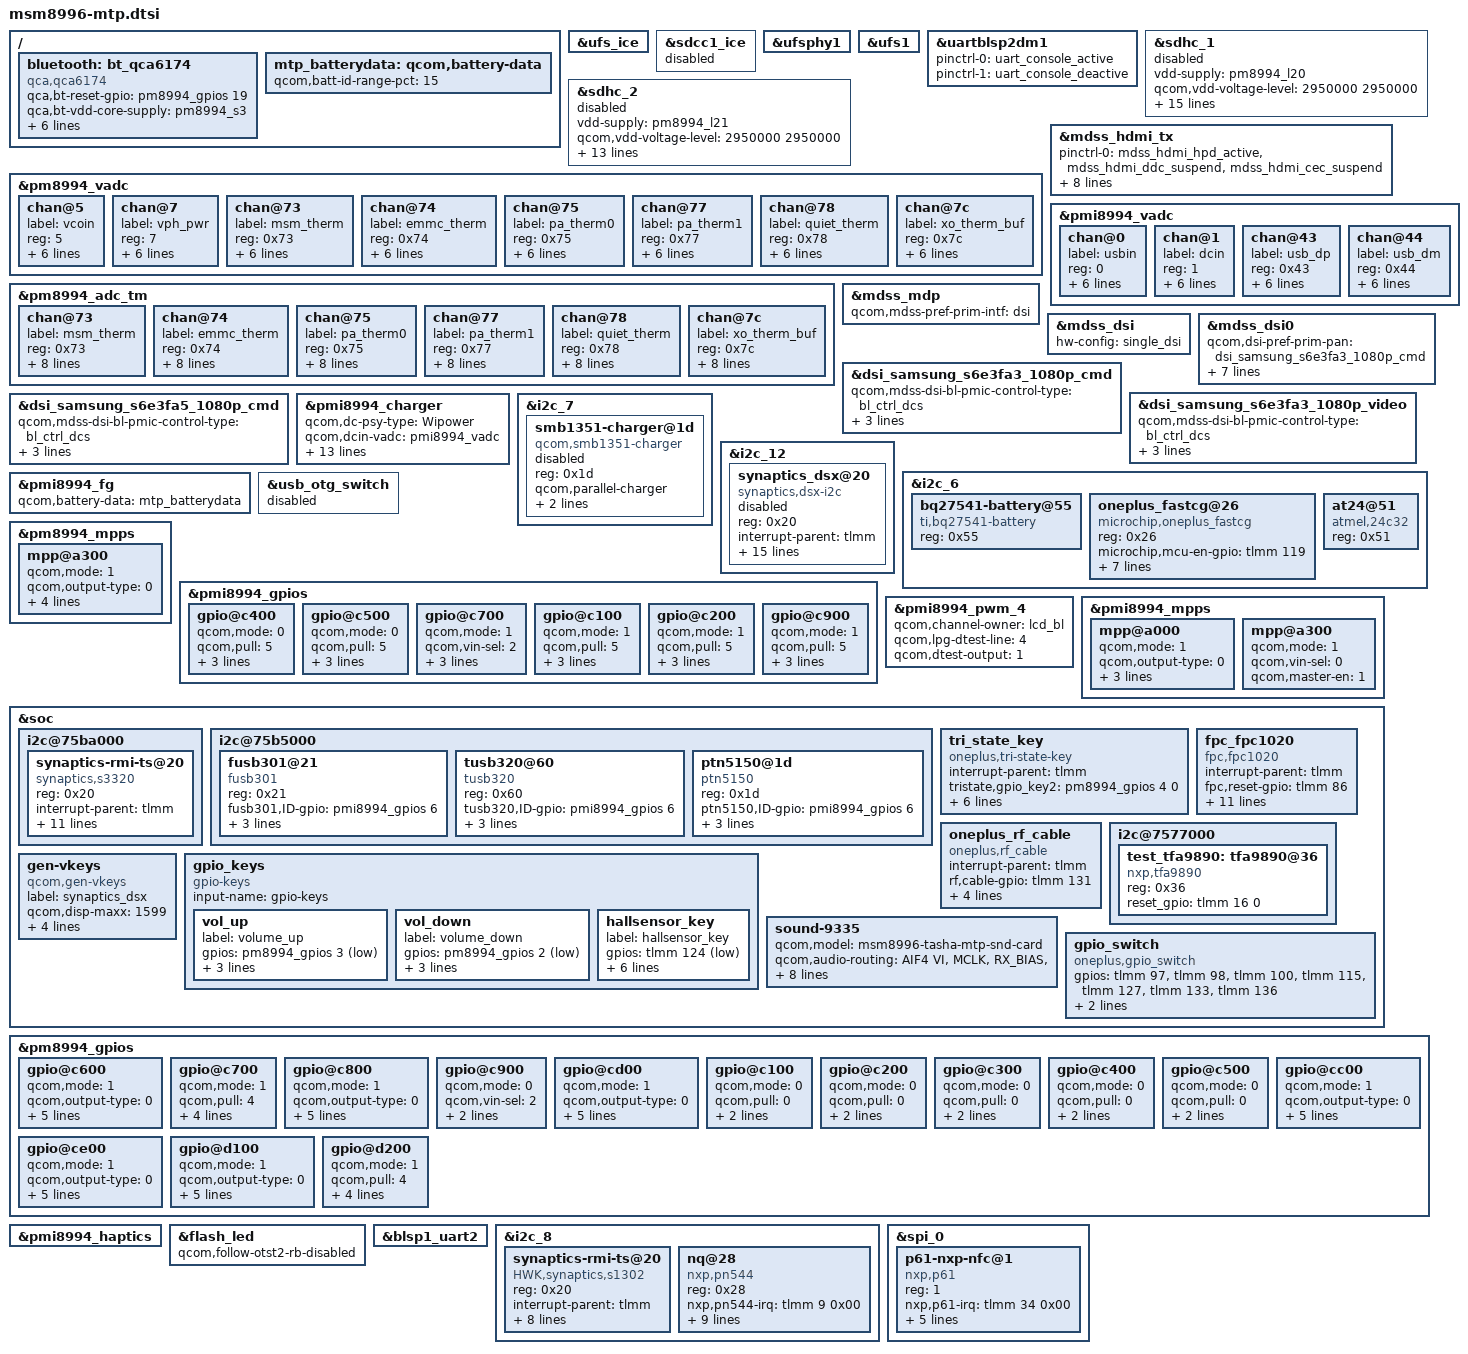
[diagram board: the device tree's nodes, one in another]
/* Copyright (c) 2015, The Linux Foundation. All rights reserved.
 *
 * This program is free software; you can redistribute it and/or modify
 * it under the terms of the GNU General Public License version 2 and
 * only version 2 as published by the Free Software Foundation.
 *
 * This program is distributed in the hope that it will be useful,
 * but WITHOUT ANY WARRANTY; without even the implied warranty of
 * MERCHANTABILITY or FITNESS FOR A PARTICULAR PURPOSE.  See the
 * GNU General Public License for more details.
 */

#include "msm8996-pinctrl.dtsi"
#include "msm8996-camera-sensor-mtp.dtsi"
#include "dsi-panel-samsung_s6e3fa3_1080p_cmd.dtsi"  //guozhiming modify for lcd 2015-10-15


/ {
	bluetooth: bt_qca6174 {
		compatible = "qca,qca6174";
		qca,bt-reset-gpio = <&pm8994_gpios 19 0>; /* BT_EN */
		qca,bt-vdd-core-supply = <&pm8994_s3>;
		qca,bt-vdd-pa-supply = <&rome_vreg>;
		qca,bt-vdd-io-supply = <&pm8994_s4>;
		qca,bt-vdd-xtal-supply = <&pm8994_l30>;
		qca,bt-chip-pwd-voltage-level = <1300000 1300000>;
		qca,bt-vdd-io-voltage-level = <1800000 1800000>;
		qca,bt-vdd-xtal-voltage-level = <1800000 1800000>;
	};
};

&ufs_ice {
        status = "ok";
};

&sdcc1_ice {
        /*zuoyonghua@connectivity 2015 12 07 hw11(T0) we used ufs , don't used emmc ,so disable it*/
        status = "disabled";
};

&ufsphy1 {
	status = "ok";
};

&ufs1 {
	status = "ok";
};

&uartblsp2dm1 {
	status = "ok";
	pinctrl-names = "uart_active", "uart_deactive";
	pinctrl-0 = <&uart_console_active>;
	pinctrl-1 = <&uart_console_deactive>;
};

&sdhc_1 {
	vdd-supply = <&pm8994_l20>;
	qcom,vdd-voltage-level = <2950000 2950000>;
	qcom,vdd-current-level = <200 570000>;

	vdd-io-supply = <&pm8994_s4>;
	qcom,vdd-io-always-on;
	qcom,vdd-io-voltage-level = <1800000 1800000>;
	qcom,vdd-io-current-level = <110 325000>;

	pinctrl-names = "active", "sleep";
	pinctrl-0 = <&sdc1_clk_on &sdc1_cmd_on &sdc1_data_on &sdc1_rclk_on>;
	pinctrl-1 = <&sdc1_clk_off &sdc1_cmd_off &sdc1_data_off &sdc1_rclk_off>;

	qcom,clk-rates = <400000 20000000 25000000 50000000 96000000 192000000 384000000>;
	qcom,ice-clk-rates = <300000000 150000000>;
	qcom,nonremovable;
	qcom,bus-speed-mode = "HS400_1p8v", "HS200_1p8v", "DDR_1p8v";

	/*zuoyonghua@connectivity 2015 12 07 hw11(T0) we used ufs , don't used emmc ,so disable it*/
	status = "disabled";
};

&sdhc_2 {
	vdd-supply = <&pm8994_l21>;
	qcom,vdd-voltage-level = <2950000 2950000>;
	qcom,vdd-current-level = <200 800000>;

	vdd-io-supply = <&pm8994_l13>;
	qcom,vdd-io-voltage-level = <1800000 2950000>;
	qcom,vdd-io-current-level = <200 22000>;

	pinctrl-names = "active", "sleep";
	pinctrl-0 = <&sdc2_clk_on  &sdc2_cmd_on &sdc2_data_on &sdc2_cd_on>;
	pinctrl-1 = <&sdc2_clk_off &sdc2_cmd_off &sdc2_data_off &sdc2_cd_off>;

	qcom,clk-rates = <400000 20000000 25000000 50000000 100000000 200000000>;
	qcom,bus-speed-mode = "SDR12", "SDR25", "SDR50", "DDR50", "SDR104";

	cd-gpios = <&tlmm 95 0x1>;
	/*lyb@bsp 11/17/15: 15801 L13/L21 don't used for MicroSD*/
	status = "disable";
};

&pm8994_vadc {
	chan@5 {
		label = "vcoin";
		reg = <5>;
		qcom,decimation = <0>;
		qcom,pre-div-channel-scaling = <1>;
		qcom,calibration-type = "absolute";
		qcom,scale-function = <0>;
		qcom,hw-settle-time = <0>;
		qcom,fast-avg-setup = <0>;
	};

	chan@7 {
		label = "vph_pwr";
		reg = <7>;
		qcom,decimation = <0>;
		qcom,pre-div-channel-scaling = <1>;
		qcom,calibration-type = "absolute";
		qcom,scale-function = <0>;
		qcom,hw-settle-time = <0>;
		qcom,fast-avg-setup = <0>;
	};

	chan@73 {
		label = "msm_therm";
		reg = <0x73>;
		qcom,decimation = <0>;
		qcom,pre-div-channel-scaling = <0>;
		qcom,calibration-type = "ratiometric";
		qcom,scale-function = <2>;
		qcom,hw-settle-time = <2>;
		qcom,fast-avg-setup = <0>;
	};

	chan@74 {
		label = "emmc_therm";
		reg = <0x74>;
		qcom,decimation = <0>;
		qcom,pre-div-channel-scaling = <0>;
		qcom,calibration-type = "ratiometric";
		qcom,scale-function = <2>;
		qcom,hw-settle-time = <2>;
		qcom,fast-avg-setup = <0>;
	};

	chan@75 {
		label = "pa_therm0";
		reg = <0x75>;
		qcom,decimation = <0>;
		qcom,pre-div-channel-scaling = <0>;
		qcom,calibration-type = "ratiometric";
		qcom,scale-function = <2>;
		qcom,hw-settle-time = <2>;
		qcom,fast-avg-setup = <0>;
	};

	chan@77 {
		label = "pa_therm1";
		reg = <0x77>;
		qcom,decimation = <0>;
		qcom,pre-div-channel-scaling = <0>;
		qcom,calibration-type = "ratiometric";
		qcom,scale-function = <2>;
		qcom,hw-settle-time = <2>;
		qcom,fast-avg-setup = <0>;
	};

	chan@78 {
		label = "quiet_therm";
		reg = <0x78>;
		qcom,decimation = <0>;
		qcom,pre-div-channel-scaling = <0>;
		qcom,calibration-type = "ratiometric";
		qcom,scale-function = <2>;
		qcom,hw-settle-time = <2>;
		qcom,fast-avg-setup = <0>;
	};

	chan@7c {
		label = "xo_therm_buf";
		reg = <0x7c>;
		qcom,decimation = <0>;
		qcom,pre-div-channel-scaling = <0>;
		qcom,calibration-type = "ratiometric";
		qcom,scale-function = <4>;
		qcom,hw-settle-time = <2>;
		qcom,fast-avg-setup = <0>;
	};

	chan@7c {
		label = "xo_therm_buf";
		reg = <0x7c>;
		qcom,decimation = <0>;
		qcom,pre-div-channel-scaling = <0>;
		qcom,calibration-type = "ratiometric";
		qcom,scale-function = <4>;
		qcom,hw-settle-time = <2>;
		qcom,fast-avg-setup = <0>;
	};
};

&pm8994_adc_tm {
	chan@73 {
		label = "msm_therm";
		reg = <0x73>;
		qcom,decimation = <0>;
		qcom,pre-div-channel-scaling = <0>;
		qcom,calibration-type = "ratiometric";
		qcom,scale-function = <2>;
		qcom,hw-settle-time = <2>;
		qcom,fast-avg-setup = <0>;
		qcom,btm-channel-number = <0x48>;
		qcom,thermal-node;
	};

	chan@74 {
		label = "emmc_therm";
		reg = <0x74>;
		qcom,decimation = <0>;
		qcom,pre-div-channel-scaling = <0>;
		qcom,calibration-type = "ratiometric";
		qcom,scale-function = <2>;
		qcom,hw-settle-time = <2>;
		qcom,fast-avg-setup = <0>;
		qcom,btm-channel-number = <0x68>;
		qcom,thermal-node;
	};

	chan@75 {
		label = "pa_therm0";
		reg = <0x75>;
		qcom,decimation = <0>;
		qcom,pre-div-channel-scaling = <0>;
		qcom,calibration-type = "ratiometric";
		qcom,scale-function = <2>;
		qcom,hw-settle-time = <2>;
		qcom,fast-avg-setup = <0>;
		qcom,btm-channel-number = <0x70>;
		qcom,thermal-node;
	};

	chan@77 {
		label = "pa_therm1";
		reg = <0x77>;
		qcom,decimation = <0>;
		qcom,pre-div-channel-scaling = <0>;
		qcom,calibration-type = "ratiometric";
		qcom,scale-function = <2>;
		qcom,hw-settle-time = <2>;
		qcom,fast-avg-setup = <0>;
		qcom,btm-channel-number = <0x78>;
		qcom,thermal-node;
	};

	chan@78 {
		label = "quiet_therm";
		reg = <0x78>;
		qcom,decimation = <0>;
		qcom,pre-div-channel-scaling = <0>;
		qcom,calibration-type = "ratiometric";
		qcom,scale-function = <2>;
		qcom,hw-settle-time = <2>;
		qcom,fast-avg-setup = <0>;
		qcom,btm-channel-number = <0x80>;
		qcom,thermal-node;
	};

	chan@7c {
		label = "xo_therm_buf";
		reg = <0x7c>;
		qcom,decimation = <0>;
		qcom,pre-div-channel-scaling = <0>;
		qcom,calibration-type = "ratiometric";
		qcom,scale-function = <4>;
		qcom,hw-settle-time = <2>;
		qcom,fast-avg-setup = <0>;
		qcom,btm-channel-number = <0x88>;
		qcom,thermal-node;
	};
};

&mdss_hdmi_tx {
	pinctrl-names = "hdmi_hpd_active", "hdmi_ddc_active", "hdmi_cec_active",
				"hdmi_active", "hdmi_sleep";
	pinctrl-0 = <&mdss_hdmi_hpd_active &mdss_hdmi_ddc_suspend
						&mdss_hdmi_cec_suspend>;
	pinctrl-1 = <&mdss_hdmi_hpd_active &mdss_hdmi_ddc_active
						&mdss_hdmi_cec_suspend>;
	pinctrl-2 = <&mdss_hdmi_hpd_active &mdss_hdmi_cec_active
						&mdss_hdmi_ddc_suspend>;
	pinctrl-3 = <&mdss_hdmi_hpd_active &mdss_hdmi_ddc_active
						&mdss_hdmi_cec_active>;
	pinctrl-4 = <&mdss_hdmi_hpd_suspend &mdss_hdmi_ddc_suspend
						&mdss_hdmi_cec_suspend>;
};

&pmi8994_vadc {
	chan@0 {
		label = "usbin";
		reg = <0>;
		qcom,decimation = <0>;
		qcom,pre-div-channel-scaling = <4>;
		qcom,calibration-type = "absolute";
		qcom,scale-function = <0>;
		qcom,hw-settle-time = <0>;
		qcom,fast-avg-setup = <0>;
	};

	chan@1 {
		label = "dcin";
		reg = <1>;
		qcom,decimation = <0>;
		qcom,pre-div-channel-scaling = <4>;
		qcom,calibration-type = "absolute";
		qcom,scale-function = <0>;
		qcom,hw-settle-time = <0>;
		qcom,fast-avg-setup = <0>;
	};

	chan@43 {
		label = "usb_dp";
		reg = <0x43>;
		qcom,decimation = <0>;
		qcom,pre-div-channel-scaling = <1>;
		qcom,calibration-type = "absolute";
		qcom,scale-function = <0>;
		qcom,hw-settle-time = <0>;
		qcom,fast-avg-setup = <0>;
	};

	chan@44 {
		label = "usb_dm";
		reg = <0x44>;
		qcom,decimation = <0>;
		qcom,pre-div-channel-scaling = <1>;
		qcom,calibration-type = "absolute";
		qcom,scale-function = <0>;
		qcom,hw-settle-time = <0>;
		qcom,fast-avg-setup = <0>;
	};
};

#include "msm8996-mdss-panels.dtsi"


/*  //guozhiming modify for lcd 2015-10-15
&mdss_mdp {
	qcom,mdss-pref-prim-intf = "dsi";
};

&mdss_dsi {
	hw-config = "split_dsi";
};

&mdss_dsi0 {
	qcom,dsi-pref-prim-pan = <&dsi_dual_sharp_video>;
	pinctrl-names = "mdss_default", "mdss_sleep";
	pinctrl-0 = <&mdss_dsi_active &mdss_te_active>;
	pinctrl-1 = <&mdss_dsi_suspend &mdss_te_suspend>;
	qcom,platform-te-gpio = <&tlmm 10 0>;
	qcom,platform-reset-gpio = <&tlmm 8 0>;
	qcom,platform-bklight-en-gpio = <&pm8994_gpios 14 0>;
};

*/
//guozhiming modify for lcd 2015-10-15
&mdss_mdp {
	qcom,mdss-pref-prim-intf = "dsi";
};
&mdss_dsi {
	hw-config = "single_dsi";
};
&mdss_dsi0 {
	qcom,dsi-pref-prim-pan = <&dsi_samsung_s6e3fa3_1080p_cmd>;
	pinctrl-names = "mdss_default", "mdss_sleep";
	pinctrl-0 = <&mdss_dsi_active &mdss_te_active &mdss_exits_active &mdss_err_active>;
	pinctrl-1 = <&mdss_dsi_suspend &mdss_te_suspend &mdss_exits_suspend &mdss_err_suspend>;
	qcom,platform-te-gpio = <&tlmm 11 0>;
	qcom,platform-reset-gpio = <&tlmm 8 0>;
	//qcom,platform-esd-te-gpio = <&tlmm 11 0>;
	qcom,lcd-vddi-en-gpio = <&tlmm 26 0>;
};

&dsi_samsung_s6e3fa3_1080p_cmd {
	qcom,mdss-dsi-bl-pmic-control-type = "bl_ctrl_dcs";
	qcom,cont-splash-enabled;
	qcom,panel-supply-entries = <&dsi_panel_pwr_supply_no_labibb>;
};

&dsi_samsung_s6e3fa3_1080p_video {
       qcom,mdss-dsi-bl-pmic-control-type = "bl_ctrl_dcs";
       qcom,cont-splash-enabled;
       qcom,panel-supply-entries = <&dsi_panel_pwr_supply_no_labibb>;
};

&dsi_samsung_s6e3fa5_1080p_cmd {
	qcom,mdss-dsi-bl-pmic-control-type = "bl_ctrl_dcs";
	qcom,cont-splash-enabled;
	qcom,panel-supply-entries = <&dsi_panel_pwr_supply_no_labibb>;
};


/{
	mtp_batterydata: qcom,battery-data {
		qcom,batt-id-range-pct = <15>;
		#include "batterydata-itech-3000mah.dtsi"
	};
};

&pmi8994_charger {
	qcom,dc-psy-type = "Wipower";
	qcom,dcin-vadc = <&pmi8994_vadc>;
	qcom,wipower-default-ilim-map = <4000000 20000000 550 700 300>;
	qcom,wipower-pt-ilim-map = <4000000 7140000 550 700 300>,
					<7140000 8140000 550 700 300>,
					<8140000 9140000 500 700 300>,
					<9140000 9950000 500 700 300>;
	qcom,wipower-div2-ilim-map = <4000000 4820000 550 700 300>,
					<4820000 5820000 550 700 300>,
					<5820000 6820000 550 650 650>,
					<6820000 7820000 550 700 600>,
					<7820000 8500000 550 700 550>;
};

&i2c_7 {
	smb1351-charger@1d {
		compatible = "qcom,smb1351-charger";
		status = "disabled";
		reg = <0x1d>;
		qcom,parallel-charger;
		qcom,float-voltage-mv = <4400>;
		qcom,recharge-mv = <100>;
	};
};

&i2c_12 {
		synaptics_dsx@20 {
			compatible = "synaptics,dsx-i2c";
			reg = <0x20>;
			status = "disabled"; //T0 use new TP and LCD
			interrupt-parent = <&tlmm>;
			interrupts = <125 0x2008>;
			vdd_ana-supply = <&pm8994_l22>;
			vcc_i2c-supply = <&pm8994_s4>;
			synaptics,pwr-reg-name = "vdd_ana";
			synaptics,bus-reg-name = "vcc_i2c";
			synaptics,irq-gpio = <&tlmm 125 0x2008>;
			synaptics,irq-on-state = <0>;
			synaptics,irq-flags = <0x2008>; /* IRQF_ONESHOT | IRQF_TRIGGER_LOW */
			synaptics,power-gpio = <&tlmm 49 0x00>;
			synaptics,power-on-state = <1>;
			synaptics,power-delay-ms = <200>;
			synaptics,reset-delay-ms = <200>;
			synaptics,max-y-for-2d = <1919>; /* remove if no virtual buttons */
			//synaptics,vir-button-codes = <102 100 900 100 60 158 300 900 100 60>;
                        pinctrl-names = "pmx_ts_active", "pmx_ts_suspend";
                        pinctrl-0 = <&ts_active>;
                        pinctrl-1 = <&ts_suspend>;

		};
};

&i2c_6 {
	bq27541-battery@55 {
		status = "ok";
		compatible = "ti,bq27541-battery";
		reg = <0x55>;
	};
	oneplus_fastcg@26{
		status = "ok";
		compatible = "microchip,oneplus_fastcg";
		reg = <0x26>;
		microchip,mcu-en-gpio = <&tlmm 119 0x00>;
		microchip,usb-sw-gpio = <&tlmm 135 0x00>;
		microchip,ap-clk = <&tlmm 75 0x00>;
		microchip,ap-data = <&tlmm 74 0x00>;

		pinctrl-names = "mux_fastchg_active", "mux_fastchg_suspend";
		pinctrl-0 = <&fastchg_active &usb_sw_active &ap_clk_active &ap_data_active>;
		pinctrl-1 = <&usb_sw_suspend &fastchg_suspend &ap_clk_suspend &ap_data_suspend>;
	};
};

&pmi8994_fg {
	qcom,battery-data = <&mtp_batterydata>;
	//qcom,ext-sense-type;	/*Yangfangbiao removed to use internal sense*/
};

&usb_otg_switch {
	status = "disabled";//changhua change from okay to disabled
};

&pm8994_mpps {
	mpp@a300 { /* MPP 4 */
		/* HDMI_5v_vreg regulator enable */
		qcom,mode = <1>;		/* Digital output */
		qcom,output-type = <0>;		/* CMOS logic */
		qcom,vin-sel = <2>;		/* S4 1.8V */
		qcom,src-sel = <0>;		/* Constant */
		qcom,master-en = <1>;		/* Enable GPIO */
		qcom,invert = <0>;
		status = "okay";
	};
};

&pmi8994_gpios {
		gpio@c400 {//pmi8996 gpio 5 type-c IC INT pin
			qcom,mode = <0>;
			qcom,pull = <5>;
			qcom,vin-sel = <2>;
			qcom,src-sel = <0>;
			qcom,master-en = <1>;
			status = "okay";

		};

		gpio@c500 {//pmi8996 gpio 6 type-c IC OTG_USB_ID pin
			qcom,mode = <0>;
			qcom,pull = <5>;
			qcom,vin-sel = <2>;
			qcom,src-sel = <0>;
			qcom,master-en = <1>;
			status = "okay";
		};
};

&pmi8994_gpios {
	gpio@c700 {	/* GPIO 8, lcd_reg_en, 5V boost  */
		qcom,mode = <1>;
		qcom,vin-sel = <2>;
		qcom,src-sel = <0>;
		qcom,invert = <1>;   /* need invert = 0 */
		qcom,master-en = <1>;
		status = "okay";
	};

	gpio@c100 {	/* GPIO 2  SPKR_SD_N */
		qcom,mode = <1>;	/* DIGITAL OUT */
		qcom,pull = <5>;	/* No Pull */
		qcom,vin-sel = <2>;	/* 1.8 */
		qcom,src-sel = <0>;	/* CONSTANT */
		qcom,master-en = <1>;	/* ENABLE GPIO */
		status = "okay";
	};

	gpio@c200 {	/* GPIO 3 SPKR_SD_N */
		qcom,mode = <1>;	/* DIGITAL OUT */
		qcom,pull = <5>;	/* No Pull */
		qcom,vin-sel = <2>;	/* 1.8 */
		qcom,src-sel = <0>;	/* CONSTANT */
		qcom,master-en = <1>;	/* ENABLE GPIO */
		status = "okay";
	};

	gpio@c900 { /* GPIO 10 - HPH_EN1 */
		qcom,mode = <1>;
		qcom,pull = <5>;
		qcom,vin-sel = <2>;
		qcom,src-sel = <2>;
		qcom,master-en = <1>;
		status = "okay";
	};
};

&pmi8994_pwm_4 {
	qcom,channel-owner = "lcd_bl";
	qcom,lpg-dtest-line = <4>;
	qcom,dtest-output = <1>;
	status = "okay";
};

&pmi8994_mpps {
	mpp@a000 { /* MPP 1 */
		qcom,mode = <1>;                /* Digital output */
		qcom,output-type = <0>;         /* CMOS logic */
		qcom,vin-sel = <2>;             /* S4 1.8V */
		qcom,src-sel = <7>;             /* DTEST4 */
		qcom,master-en = <1>;           /* Enable MPP */
		status = "okay";
	};

	mpp@a300 { /* MPP 4 */
		/* WLED FET */
		qcom,mode = <1>;        /* DIGITAL OUT */
		qcom,vin-sel = <0>;     /* VIN0 */
		qcom,master-en = <1>;
		status = "okay";
	};
};

&soc {
/*
	i2c@75ba000 {
		synaptics@20 {
			compatible = "synaptics,dsx";
			reg = <0x20>;
			interrupt-parent = <&tlmm>;
			interrupts = <125 0x2008>;
			vdd-supply = <&pm8994_l14>;
			avdd-supply = <&pm8994_l22>;
			pinctrl-names = "pmx_ts_active", "pmx_ts_suspend";
			pinctrl-0 = <&ts_active>;
			pinctrl-1 = <&ts_suspend>;
			synaptics,display-coords = <0 0 1079 1918>;
			synaptics,panel-coords = <0 0 1079 1918>;
			synaptics,reset-gpio = <&tlmm 89 0x00>;
			synaptics,irq-gpio = <&tlmm 125 0x2008>;
			synaptics,disable-gpios;
			synaptics,fw-name = "PR1702898-s3528t_00350002.img";
			// Underlying clocks used by secure touch
			clock-names = "iface_clk", "core_clk";
			clocks = <&clock_gcc clk_gcc_blsp2_ahb_clk>,
				 <&clock_gcc clk_gcc_blsp2_qup6_i2c_apps_clk>;
		};
	};
*/
/* lifeng@BSP 2015/12/1 for synaptics tp @20 */
	i2c@75ba000 {
		synaptics-rmi-ts@20 {
			compatible = "synaptics,s3320";
			//status = "disabled"; //T0 use new TP and LCD
			reg = <0x20>;
			interrupt-parent = <&tlmm>;
			interrupts = <125 0x2008>;
			synaptics,irq-gpio = <&tlmm 125 0x2008>;
			synaptics,reset-gpio = <&tlmm 89 0x00>;
			synaptics,1v8-gpio = <&tlmm 49 0x00>;
			synaptics,tx-rx-num = <16 28>;
			synaptics,display-coords = <1080 1920>;
			vdd_2v8-supply = <&pm8994_l22>;
			vcc_i2c_1v8-supply = <&pm8994_s4>;
			oem,support_hw_poweroff;
			pinctrl-names = "pmx_ts_active", "pmx_ts_suspend";
			pinctrl-0 = <&ts_active>;
			pinctrl-1 = <&ts_suspend>;
		};
	};

	i2c@75b5000 {
		fusb301@21 {
			compatible = "fusb301";
			reg = <0x21>;
			fusb301,ID-gpio = <&pmi8994_gpios 6 0>;
			fusb301,irq-gpio = <&pmi8994_gpios 5 0>;
			// Underlying clocks used by secure touch
			clock-names = "iface_clk", "core_clk";
			clocks = <&clock_gcc clk_gcc_blsp2_ahb_clk>,
				 <&clock_gcc clk_gcc_blsp2_qup1_i2c_apps_clk>;
		};
		tusb320@60 {
			compatible = "tusb320";
			reg = <0x60>;
			tusb320,ID-gpio = <&pmi8994_gpios 6 0>;
			tusb320,irq-gpio = <&pmi8994_gpios 5 0>;
			// Underlying clocks used by secure touch
			clock-names = "iface_clk", "core_clk";
			clocks = <&clock_gcc clk_gcc_blsp2_ahb_clk>,
				 <&clock_gcc clk_gcc_blsp2_qup1_i2c_apps_clk>;
		};

		ptn5150@1d {
			compatible = "ptn5150";
			reg = <0x1d>;
			ptn5150,ID-gpio = <&pmi8994_gpios 6 0>;
			ptn5150,irq-gpio = <&pmi8994_gpios 5 0>;
			// Underlying clocks used by secure touch
			clock-names = "iface_clk", "core_clk";
			clocks = <&clock_gcc clk_gcc_blsp2_ahb_clk>,
				 <&clock_gcc clk_gcc_blsp2_qup1_i2c_apps_clk>;
		};

	};

	tri_state_key {
		compatible = "oneplus,tri-state-key";
		interrupt-parent = <&tlmm>;
		tristate,gpio_key2 = <&pm8994_gpios 4 0>;
		tristate,gpio_key1 = <&pm8994_gpios 6 0>;
		tristate,gpio_key3 = <&pm8994_gpios 5 0>;
		//vdd_io-supply = <&pm8994_s4>;  // 1.8V

		#pinctrl-names = "pmx_tri_state_key_active", "pmx_tri_state_key_suspend";
		#pinctrl-0 = <&tri_state_key_active>;
		#pinctrl-1 = <&tri_state_key_suspend>;
	};

	fpc_fpc1020 {
		compatible = "fpc,fpc1020";
		interrupt-parent = <&tlmm>;
		fpc,reset-gpio    = <&tlmm 86 0>;
		fpc,irq-gpio    = <&tlmm 95 0>;
		fpc,gpio_id0    = <&tlmm 25 0>;
		fpc,gpio_id1    = <&tlmm 143 0>;
		fpc,gpio_1V8_EN = <&tlmm 14 0x00>;
		#vcc_spi-supply  = <&pm8994_l13>;
		#vdd_ana-supply  = <&pm8994_l13>;
		#vdd_io-supply   = <&pm8994_s4>;

		#pinctrl-names = "pmx_tri_state_key_active", "pmx_tri_state_key_suspend";
		#pinctrl-0 = <&tri_state_key_active>;
		#pinctrl-1 = <&tri_state_key_suspend>;
	};

	oneplus_rf_cable {
		compatible = "oneplus,rf_cable";
		interrupt-parent = <&tlmm>;
		rf,cable-gpio    = <&tlmm 131 0>;

		#pinctrl-names = "pmx_tri_state_key_active", "pmx_tri_state_key_suspend";
		#pinctrl-0 = <&tri_state_key_active>;
		#pinctrl-1 = <&tri_state_key_suspend>;
	};

	i2c@7577000{
	    status = "ok";
        test_tfa9890:     tfa9890@36 {
		  compatible = "nxp,tfa9890";
		  reg = <0x36>;
		  reset_gpio= <&tlmm 16 0>;
		  status = "okay";
		 };
	};

	gen-vkeys {
		compatible = "qcom,gen-vkeys";
		label = "synaptics_dsx";
		qcom,disp-maxx = <1599>;
		qcom,disp-maxy = <2559>;
		qcom,panel-maxx = <1599>;
		qcom,panel-maxy = <2703>;
		qcom,key-codes = <158 139 102 217>;
	};

	gpio_keys {
		compatible = "gpio-keys";
		input-name = "gpio-keys";

		vol_up {
			label = "volume_up";
			gpios = <&pm8994_gpios 3 0x1>;
			linux,input-type = <1>;
			linux,code = <115>;
			debounce-interval = <15>;
		};

        vol_down {
			label = "volume_down";
			gpios = <&pm8994_gpios 2 0x1>;
			linux,input-type = <1>;
			linux,code = <114>;
			debounce-interval = <15>;
		};

		/*
		cam_snapshot {
			label = "cam_snapshot";
			gpios = <&pm8994_gpios 4 0x1>;
			linux,input-type = <1>;
			linux,code = <766>;
			gpio-key,wakeup;
			debounce-interval = <15>;
		};

		cam_focus {
			label = "cam_focus";
			gpios = <&pm8994_gpios 5 0x1>;
			linux,input-type = <1>;
			linux,code = <528>;
			gpio-key,wakeup;
			debounce-interval = <15>;
		};
                */

		hallsensor_key {
			label = "hallsensor_key";
			gpios = <&tlmm 124 1>;
			interrupt-parent = <&tlmm>;
			interrupts = <124 0x0>;
			linux,input-type = <5>;
			linux,code = <0>;
			gpio-key,wakeup;
			debounce-interval = <15>;
		};
	};

	sound-9335 {
		qcom,model = "msm8996-tasha-mtp-snd-card";

		qcom,audio-routing =
			"AIF4 VI", "MCLK",
			"RX_BIAS", "MCLK",
			"MADINPUT", "MCLK",
			"hifi amp", "LINEOUT1",
			"hifi amp", "LINEOUT2",

			"AMIC2", "MIC BIAS2",
			"MIC BIAS2", "Headset Mic",
			"AMIC4", "MIC BIAS1",
			"MIC BIAS1", "Primary Mic",
			"AMIC5", "MIC BIAS3",
			"MIC BIAS3", "Noise Mic";

		asoc-codec = <&stub_codec>, <&hdmi_audio>;
		asoc-codec-names = "msm-stub-codec.1", "msm-hdmi-audio-codec-rx";

	};
    gpio_switch {
		compatible = "oneplus,gpio_switch";
        gpios = <&tlmm  97 0x00>,
                <&tlmm  98 0x00>,
                <&tlmm 100 0x00>,
			    <&tlmm 115 0x00>,
			    <&tlmm 127 0x00>,
			    <&tlmm 133 0x00>,
			    <&tlmm 136 0x00>;
        pinctrl-names = "gpio_switch_pin_active", "gpio_switch_pin_suspend";
		pinctrl-0 = <&pmx_gpio_switch_pin_active>;
		pinctrl-1 = <&pmx_gpio_switch_pin_suspend>;
	};
};

&pm8994_gpios {
	gpio@c600 { /* GPIO 7 - NFC DWL REQ */
		qcom,mode = <1>;
		qcom,output-type = <0>;
		qcom,pull = <5>;
		qcom,vin-sel = <2>;
		qcom,out-strength = <3>;
		qcom,src-sel = <0>;
		qcom,master-en = <1>;
		status = "okay";
	};

	gpio@c700 { /* GPIO 8 - WLAN_EN */
		qcom,mode = <1>;		/* Digital output*/
		qcom,pull = <4>;		/* Pulldown 10uA */
		qcom,vin-sel = <2>;		/* VIN2 */
		qcom,src-sel = <0>;		/* GPIO */
		qcom,invert = <0>;		/* Invert */
		qcom,master-en = <1>;		/* Enable GPIO */
		status = "okay";
	};

	gpio@c800 { /* GPIO 9 - Rome 3.3V control */
		qcom,mode = <1>;		/* Digital output */
		qcom,output-type = <0>;		/* MOS logic */
		qcom,invert = <1>;		/* Output high */
		qcom,vin-sel = <0>;		/* VPH_PWR */
		qcom,src-sel = <0>;		/* Constant */
		qcom,out-strength = <1>;	/* High drive strength */
		qcom,master-en = <1>;		/* Enable GPIO */
		status = "okay";
	};

	gpio@c900 { /* GPIO 10 - NFC CLK _REQ*/
		qcom,mode = <0>;
		qcom,vin-sel = <2>;
		qcom,src-sel = <0>;
		qcom,master-en = <1>;
		status = "okay";
	};

	gpio@cd00 { /* GPIO 14 - lcd_bklt_reg_en */
		qcom,mode = <1>;	/* DIGITAL OUT */
		qcom,output-type = <0>;		/* CMOS logic */
		qcom,invert = <1>; 	/* output hight initially */
		qcom,vin-sel = <2>;	/* 1.8 */
		qcom,src-sel = <0>;	/* CONSTANT */
		qcom,out-strength = <1>;	/* Low drive strength */
		qcom,master-en = <1>;	/* ENABLE GPIO */
		status = "okay";
	};
	gpio@c100 { /* GPIO 2 */
		qcom,mode = <0>;
		qcom,pull = <0>;
		qcom,vin-sel = <2>;
		qcom,src-sel = <0>;
		status = "okay";
	};

	gpio@c200 { /* GPIO 3 */
		qcom,mode = <0>;
		qcom,pull = <0>;
		qcom,vin-sel = <2>;
		qcom,src-sel = <0>;
		status = "okay";
	};

	gpio@c300 { /* GPIO 4 */
		qcom,mode = <0>;
		qcom,pull = <0>;
		qcom,vin-sel = <2>;
		qcom,src-sel = <0>;
		status = "okay";
	};

	gpio@c400 { /* GPIO 5 */
		qcom,mode = <0>;
		qcom,pull = <0>;
		qcom,vin-sel = <2>;
		qcom,src-sel = <0>;
		status = "okay";
	};

	gpio@c500 { /* GPIO 6 */
		qcom,mode = <0>;
		qcom,pull = <0>;
		qcom,vin-sel = <2>;
		qcom,src-sel = <0>;
		status = "okay";
	};

	gpio@cc00 { /* GPIO 13 - HPH_EN0 */
		qcom,mode = <1>;
		qcom,output-type = <0>;
		qcom,pull = <5>;
		qcom,vin-sel = <2>;
		qcom,out-strength = <1>;
		qcom,src-sel = <2>;
		qcom,master-en = <1>;
		status = "okay";
	};

	gpio@ce00 { /* GPIO 15 */
		qcom,mode = <1>;
		qcom,output-type = <0>;
		qcom,pull = <5>;
		qcom,vin-sel = <2>;
		qcom,out-strength = <1>;
		qcom,src-sel = <2>;
		qcom,master-en = <1>;
		status = "okay";
	};

	gpio@d100 { /* GPIO 18 - Rome Sleep Clock */
		qcom,mode = <1>;		/* Digital output */
		qcom,output-type = <0>;		/* CMOS logic */
		qcom,invert = <0>;		/* Output low initially */
		qcom,vin-sel = <2>;		/* VIN 2 */
		qcom,src-sel = <3>;		/* Function 2 */
		qcom,out-strength = <2>;	/* Medium */
		qcom,master-en = <1>;		/* Enable GPIO */
		status = "okay";
	};

	gpio@d200 { /* GPIO 19 - Rome BT Reset */
		qcom,mode = <1>;		/* Digital output*/
		qcom,pull = <4>;		/* Pulldown 10uA */
		qcom,vin-sel = <2>;		/* VIN2 */
		qcom,src-sel = <0>;		/* GPIO */
		qcom,invert = <0>;		/* Invert */
		qcom,master-en = <1>;		/* Enable GPIO */
		status = "okay";
	};
};

&pmi8994_haptics {
	status = "okay";
};

&flash_led {
	qcom,follow-otst2-rb-disabled;
};

&blsp1_uart2 {
	status = "ok";
};

&i2c_6 {
	at24@51 {
		compatible = "atmel,24c32";
		reg = <0x51>;
	};
};


&i2c_8 { /* BLSP2 QUP2 */
	synaptics-rmi-ts@20 {
		compatible = "HWK,synaptics,s1302";
		reg = <0x20>;
		interrupt-parent = <&tlmm>;
		interrupts = <132 0x2008>;
		synaptics,irq-gpio = <&tlmm 132 0x2008>;
		synaptics,reset-gpio = <&tlmm 76 0x00>;
		//synaptics,en3v_gpio = <&tlmm 14 0x00>;//changhua mv to sbl cause fingerprint use the same LDO
		vdd_2v8-supply = <&pm8994_l13>;
		vcc_i2c_1v8-supply = <&pm8994_s4>;
		oem,cover_reject;//when esd test cover the phone on the panel don't report keys;

		pinctrl-names = "pmx_tk_active", "pmx_tk_suspend";
		pinctrl-0 = <&tk_active>;
		pinctrl-1 = <&tk_suspend>;
	};
    nq@28 {
		compatible = "nxp,pn544";
		reg = <0x28>;
		nxp,pn544-irq = <&tlmm 9 0x00>;
		nxp,pn544-ven = <&tlmm 94 0x00>;
		nxp,pn544-fw-dwnld = <&tlmm 12 0x00>;
		nxp,pn544-ese-pwr = <&pm8994_gpios 07 0x00>;
		nxp,pn544-clk-gpio = <&pm8994_gpios 10 0x00>;
		interrupt-parent = <&tlmm>;
		qcom,clk-src = "BBCLK2";
		interrupts = <9 0>;
		interrupt-names = "nfc_irq";
		//pinctrl-names = "nfc_active", "nfc_suspend";
		//pinctrl-0 = <&nfc_int_active &nfc_disable_active>;
		//pinctrl-1 = <&nfc_int_suspend &nfc_disable_suspend>;
		//clocks = <&clock_gcc clk_bb_clk2>;
		clocks = <&clock_gcc clk_bb_clk2_pin>;
		clock-names = "ref_clk";
		//nfc_voltage-supply = <&pm8994_l9>; /*NFC don't contrl ldo 9 .ldo 9 contrled by modem, this will cause can,t recognise sim card*/
		nfc_voltage_s4-supply = <&pm8994_s4>;
	};
};

//spi_0:
&spi_0 { /* BLSP1 QUP1 */
        p61-nxp-nfc@1 { //Slave driver and CS ID
                compatible = "nxp,p61"; //Manufacture, and Model
                reg = <1>; //Same as CS ID
                nxp,p61-irq = <&tlmm 34 0x00>; //Pass a GPIO
                nxp,p61-rst = <&tlmm 21 0x00>; //Pass a GPIO
                spi-max-frequency = <19200000>;
                spi-cs-high; //CS Active High
                interrupt-parent = <&tlmm>; //GPIO Handler
                interrupts = <34 0>; //GPIO # and flags
                //pinctrl-names = "nxp_spi_irq_active", "nxp_spi_irq_suspend";
                //pinctrl-0 = <&nfc_spi_irq_active>;
                //pinctrl-1 = <&nfc_spi_irq_suspend>;
                //#spi-cpol; //CPOL bit set for SPI polarity
                //#spi-cpha; //CPHA bit set for SPI Phase
                //nfc_voltage-supply = <&pm8994_l9>; /*NFC don't contrl ldo 9 .ldo 9 contrled by modem, this will cause can,t recognise sim card*/
        };
};
